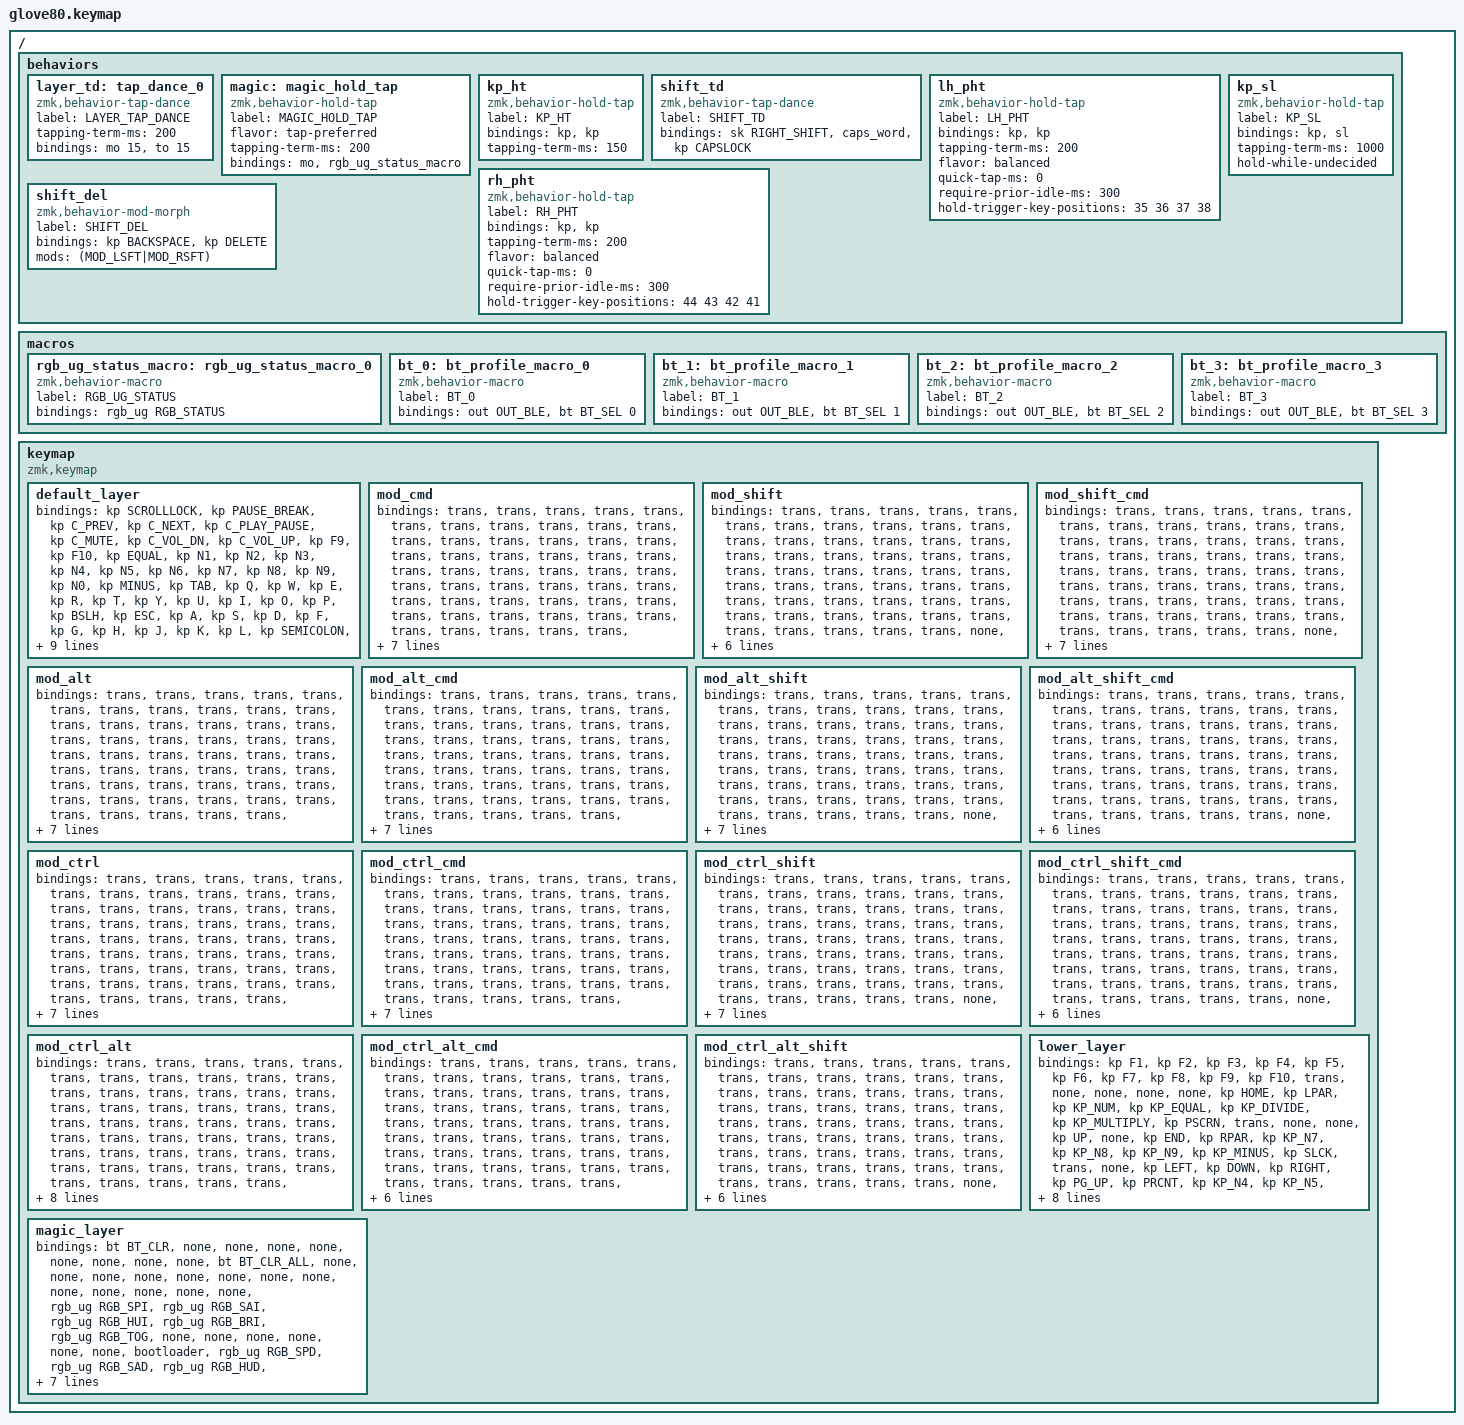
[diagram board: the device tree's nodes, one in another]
/*
 * Copyright (c) 2020 The ZMK Contributors
 *
 * SPDX-License-Identifier: MIT
 */

#include <behaviors.dtsi>
#include <dt-bindings/zmk/bt.h>
#include <dt-bindings/zmk/keys.h>
#include <dt-bindings/zmk/outputs.h>
#include <dt-bindings/zmk/rgb.h>

#define HYPER LC(LS(LG(LALT)))

// layers

#define DEFAULT 0
#define LOWER 1
#define MAGIC 2
#define FACTORY_TEST 3

/ {
    behaviors {
        // For the "layer" key, it'd nice to be able to use it as either a shift or a toggle.
        // Configure it as a tap dance, so the first tap (or hold) is a &mo and the second tap is a &to

        layer_td: tap_dance_0 {
            compatible = "zmk,behavior-tap-dance";
            label = "LAYER_TAP_DANCE";
            #binding-cells = <0>;
            tapping-term-ms = <200>;
            bindings = <&mo 15>, <&to 15>;
        };

        magic: magic_hold_tap {
            compatible = "zmk,behavior-hold-tap";
            label = "MAGIC_HOLD_TAP";
            #binding-cells = <2>;
            flavor = "tap-preferred";
            tapping-term-ms = <200>;
            bindings = <&mo>, <&rgb_ug_status_macro>;
        };

        kp_ht: kp_ht {
            compatible = "zmk,behavior-hold-tap";
            label = "KP_HT";
            bindings = <&kp>, <&kp>;

            #binding-cells = <2>;
            tapping-term-ms = <150>;
        };

        shift_td: shift_td {
            compatible = "zmk,behavior-tap-dance";
            label = "SHIFT_TD";
            #binding-cells = <0>;
            bindings = <&sk RIGHT_SHIFT>, <&caps_word>, <&kp CAPSLOCK>;
        };

        lh_pht: lh_pht {
            compatible = "zmk,behavior-hold-tap";
            label = "LH_PHT";
            bindings = <&kp>, <&kp>;

            #binding-cells = <2>;
            tapping-term-ms = <200>;
            flavor = "balanced";
            quick-tap-ms = <0>;
            require-prior-idle-ms = <300>;
            hold-trigger-key-positions = <35 36 37 38>;
        };

        rh_pht: rh_pht {
            compatible = "zmk,behavior-hold-tap";
            label = "RH_PHT";
            bindings = <&kp>, <&kp>;

            #binding-cells = <2>;
            tapping-term-ms = <200>;
            flavor = "balanced";
            quick-tap-ms = <0>;
            require-prior-idle-ms = <300>;
            hold-trigger-key-positions = <44 43 42 41>;
        };

        shift_del: shift_del {
            compatible = "zmk,behavior-mod-morph";
            label = "SHIFT_DEL";
            bindings = <&kp BACKSPACE>, <&kp DELETE>;

            #binding-cells = <0>;
            mods = <(MOD_LSFT|MOD_RSFT)>;
        };

        kp_sl: kp_sl {
            compatible = "zmk,behavior-hold-tap";
            label = "KP_SL";
            bindings = <&kp>, <&sl>;

            #binding-cells = <2>;
            tapping-term-ms = <1000>;
            hold-while-undecided;
        };
    };

    macros {
        rgb_ug_status_macro: rgb_ug_status_macro_0 {
            label = "RGB_UG_STATUS";
            compatible = "zmk,behavior-macro";
            #binding-cells = <0>;
            bindings = <&rgb_ug RGB_STATUS>;
        };

        bt_0: bt_profile_macro_0 {
            label = "BT_0";
            compatible = "zmk,behavior-macro";
            #binding-cells = <0>;
            bindings = <&out OUT_BLE &bt BT_SEL 0>;
        };

        bt_1: bt_profile_macro_1 {
            label = "BT_1";
            compatible = "zmk,behavior-macro";
            #binding-cells = <0>;
            bindings = <&out OUT_BLE &bt BT_SEL 1>;
        };

        bt_2: bt_profile_macro_2 {
            label = "BT_2";
            compatible = "zmk,behavior-macro";
            #binding-cells = <0>;
            bindings = <&out OUT_BLE &bt BT_SEL 2>;
        };

        bt_3: bt_profile_macro_3 {
            label = "BT_3";
            compatible = "zmk,behavior-macro";
            #binding-cells = <0>;
            bindings = <&out OUT_BLE &bt BT_SEL 3>;
        };
    };

    keymap {
        compatible = "zmk,keymap";

        default_layer {
            // ---------------------------------------------------------------------------------------------------------------------------------
            // |  F1   |  F2 |  F3 |  F4  |  F5  |                                                               |  F6   |  F7   |  F8  |   F9  |  F10 |
            // |  =    |  1  |  2  |  3   |  4   |  5   |                                                 |  6   |   7   |   8   |  9   |   0   |   -  |
            // |  TAB  |  Q  |  W  |  E   |  R   |  T   |                                                 |  Y   |   U   |   I   |  O   |   P   |   \  |
            // |  ESC  |  A  |  S  |  D   |  F   |  G   |                                                 |  H   |   J   |   K   |  L   |   ;   |   '  |
            // |   `   |  Z  |  X  |  C   |  V   |  B   | LSHFT | LCTRL | LOWER | | LGUI  | RCTRL | RSHFT |  N   |   M   |   ,   |  .   |   /   | PGUP |
            // | MAGIC | HOME| END | LEFT | RIGHT|      | BSPC  | DEL   | LALT  | | RALT  | RET   | SPACE |      |  UP   | DOWN  |  [   |   ]   | PGDN |

            bindings = <
&kp SCROLLLOCK  &kp PAUSE_BREAK  &kp C_PREV  &kp C_NEXT  &kp C_PLAY_PAUSE                                                                                                                &kp C_MUTE  &kp C_VOL_DN  &kp C_VOL_UP  &kp F9         &kp F10
&kp EQUAL       &kp N1           &kp N2      &kp N3      &kp N4            &kp N5                                                                                                &kp N6  &kp N7      &kp N8        &kp N9        &kp N0         &kp MINUS
&kp TAB         &kp Q            &kp W       &kp E       &kp R             &kp T                                                                                                 &kp Y   &kp U       &kp I         &kp O         &kp P          &kp BSLH
&kp ESC         &kp A            &kp S       &kp D       &kp F             &kp G                                                                                                 &kp H   &kp J       &kp K         &kp L         &kp SEMICOLON  &kp SQT
&kp GRAVE       &kp Z            &kp X       &kp C       &kp V             &kp B   &kp_sl LSHFT 2  &kp_sl LCMD 1   &layer_td      &kp_sl RCTRL 8  &kp_sl RGUI 1  &kp_sl RSHFT 2  &kp N   &kp M       &kp COMMA     &kp DOT       &kp FSLH       &kp PG_UP
&magic 16 0     &kp HOME         &kp END     &kp LEFT    &kp RIGHT                 &shift_del      &kp_sl LCTRL 8  &kp_sl LALT 4  &kp_sl RALT 4   &kp RET        &kp SPACE               &kp UP      &kp DOWN      &kp LBKT      &kp RBKT       &kp PG_DN
            >;
        };

        mod_cmd {
            bindings = <
&trans  &trans  &trans  &trans  &trans                                                                                                                             &trans  &trans  &trans  &trans  &trans
&trans  &trans  &trans  &trans  &trans  &trans                                                                                                             &trans  &trans  &trans  &trans  &trans  &trans
&trans  &trans  &trans  &trans  &trans  &trans                                                                                                             &trans  &trans  &trans  &trans  &trans  &trans
&trans  &trans  &trans  &trans  &trans  &trans                                                                                                             &trans  &trans  &trans  &trans  &trans  &trans
&trans  &trans  &trans  &trans  &trans  &trans  &kp_sl LG(LSHFT) 3  &none               &trans             &kp_sl RG(RCTRL) 9  &none   &kp_sl RG(RSHFT) 3  &trans  &trans  &trans  &trans  &trans  &trans
&trans  &trans  &trans  &trans  &trans          &trans              &kp_sl LG(LCTRL) 9  &kp_sl LG(LALT) 5  &kp_sl RG(RALT) 5   &trans  &trans                      &trans  &trans  &trans  &trans  &trans
            >;
        };

        mod_shift {
            bindings = <
&trans  &trans  &trans  &trans  &trans                                                                                                                  &trans  &trans  &trans  &trans  &trans
&trans  &trans  &trans  &trans  &trans  &trans                                                                                                  &trans  &trans  &trans  &trans  &trans  &trans
&trans  &trans  &trans  &trans  &trans  &trans                                                                                                  &trans  &trans  &trans  &trans  &trans  &trans
&trans  &trans  &trans  &trans  &trans  &trans                                                                                                  &trans  &trans  &trans  &trans  &trans  &trans
&trans  &trans  &trans  &trans  &trans  &trans  &none   &kp_sl LS(LGUI) 3    &trans             &kp_sl RS(RCTRL) 10  &kp_sl RS(RGUI) 3  &none   &trans  &trans  &trans  &trans  &trans  &trans
&trans  &trans  &trans  &trans  &trans          &trans  &kp_sl LS(LCTRL) 10  &kp_sl LS(LALT) 6  &kp_sl RS(RALT) 6    &trans             &trans          &trans  &trans  &trans  &trans  &trans
            >;
        };

        mod_shift_cmd {
            bindings = <
&trans  &trans  &trans  &trans  &trans                                                                                                                   &trans  &trans  &trans  &trans  &trans
&trans  &trans  &trans  &trans  &trans  &trans                                                                                                   &trans  &trans  &trans  &trans  &trans  &trans
&trans  &trans  &trans  &trans  &trans  &trans                                                                                                   &trans  &trans  &trans  &trans  &trans  &trans
&trans  &trans  &trans  &trans  &trans  &trans                                                                                                   &trans  &trans  &trans  &trans  &trans  &trans
&trans  &trans  &trans  &trans  &trans  &trans  &none   &none                    &trans                 &kp_sl RS(RG(RCTRL)) 11  &none   &none   &trans  &trans  &trans  &trans  &trans  &trans
&trans  &trans  &trans  &trans  &trans          &trans  &kp_sl LS(LG(LCTRL)) 11  &kp_sl LS(LG(LALT)) 7  &kp_sl RS(RG(RALT)) 7    &trans  &trans          &trans  &trans  &trans  &trans  &trans
            >;
        };

        mod_alt {
            bindings = <
&trans  &trans  &trans  &trans  &trans                                                                                                                               &trans  &trans  &trans  &trans  &trans
&trans  &trans  &trans  &trans  &trans  &trans                                                                                                               &trans  &trans  &trans  &trans  &trans  &trans
&trans  &trans  &trans  &trans  &trans  &trans                                                                                                               &trans  &trans  &trans  &trans  &trans  &trans
&trans  &trans  &trans  &trans  &trans  &trans                                                                                                               &trans  &trans  &trans  &trans  &trans  &trans
&trans  &trans  &trans  &trans  &trans  &trans  &kp_sl LA(LSHFT) 6  &kp_sl LA(LCMD) 5    &trans  &kp_sl RA(RCTRL) 12  &kp_sl RA(RCMD) 5  &kp_sl RA(RSHFT) 6  &trans  &trans  &trans  &trans  &trans  &trans
&trans  &trans  &trans  &trans  &trans          &trans              &kp_sl LA(LCTRL) 12  &none   &none                &trans             &trans                      &trans  &trans  &trans  &trans  &trans
            >;
        };

        mod_alt_cmd {
            bindings = <
&trans  &trans  &trans  &trans  &trans                                                                                                                                     &trans  &trans  &trans  &trans  &trans
&trans  &trans  &trans  &trans  &trans  &trans                                                                                                                     &trans  &trans  &trans  &trans  &trans  &trans
&trans  &trans  &trans  &trans  &trans  &trans                                                                                                                     &trans  &trans  &trans  &trans  &trans  &trans
&trans  &trans  &trans  &trans  &trans  &trans                                                                                                                     &trans  &trans  &trans  &trans  &trans  &trans
&trans  &trans  &trans  &trans  &trans  &trans  &kp_sl LA(LG(LSHIFT)) 7  &none                    &trans  &kp_sl RA(RG(RCTRL)) 13  &none   &kp_sl RA(RG(RSHFT)) 7  &trans  &trans  &trans  &trans  &trans  &trans
&trans  &trans  &trans  &trans  &trans          &trans                   &kp_sl LA(LG(LCTRL)) 13  &none   &none                    &trans  &trans                          &trans  &trans  &trans  &trans  &trans
            >;
        };

        mod_alt_shift {
            bindings = <
&trans  &trans  &trans  &trans  &trans                                                                                                                   &trans  &trans  &trans  &trans  &trans
&trans  &trans  &trans  &trans  &trans  &trans                                                                                                   &trans  &trans  &trans  &trans  &trans  &trans
&trans  &trans  &trans  &trans  &trans  &trans                                                                                                   &trans  &trans  &trans  &trans  &trans  &trans
&trans  &trans  &trans  &trans  &trans  &trans                                                                                                   &trans  &trans  &trans  &trans  &trans  &trans
&trans  &trans  &trans  &trans  &trans  &trans  &none   &kp_sl LS(LA(LCMD)) 7    &trans  &kp_sl RA(RS(RCTRL)) 14  &kp_sl RA(RS(RCMD)) 7  &none   &trans  &trans  &trans  &trans  &trans  &trans
&trans  &trans  &trans  &trans  &trans          &trans  &kp_sl LS(LA(LCTRL)) 14  &none   &none                    &trans                 &trans          &trans  &trans  &trans  &trans  &trans
            >;
        };

        mod_alt_shift_cmd {
            bindings = <
&trans  &trans  &trans  &trans  &trans                                                                                                &trans  &trans  &trans  &trans  &trans
&trans  &trans  &trans  &trans  &trans  &trans                                                                                &trans  &trans  &trans  &trans  &trans  &trans
&trans  &trans  &trans  &trans  &trans  &trans                                                                                &trans  &trans  &trans  &trans  &trans  &trans
&trans  &trans  &trans  &trans  &trans  &trans                                                                                &trans  &trans  &trans  &trans  &trans  &trans
&trans  &trans  &trans  &trans  &trans  &trans  &none   &none                  &trans  &kp RA(RS(RG(RCTRL)))  &none   &none   &trans  &trans  &trans  &trans  &trans  &trans
&trans  &trans  &trans  &trans  &trans          &trans  &kp LA(LS(LG(LCTRL)))  &none   &none                  &trans  &trans          &trans  &trans  &trans  &trans  &trans
            >;
        };

        mod_ctrl {
            bindings = <
&trans  &trans  &trans  &trans  &trans                                                                                                                                          &trans  &trans  &trans  &trans  &trans
&trans  &trans  &trans  &trans  &trans  &trans                                                                                                                          &trans  &trans  &trans  &trans  &trans  &trans
&trans  &trans  &trans  &trans  &trans  &trans                                                                                                                          &trans  &trans  &trans  &trans  &trans  &trans
&trans  &trans  &trans  &trans  &trans  &trans                                                                                                                          &trans  &trans  &trans  &trans  &trans  &trans
&trans  &trans  &trans  &trans  &trans  &trans  &kp_sl LC(LSHFT) 10  &kp_sl LC(LCMD) 9  &trans              &none               &kp_sl RC(RCMD) 9  &kp_sl RC(RSHFT) 10  &trans  &trans  &trans  &trans  &trans  &trans
&trans  &trans  &trans  &trans  &trans          &trans               &none              &kp_sl LC(LALT) 12  &kp_sl RC(RALT) 12  &trans             &trans                       &trans  &trans  &trans  &trans  &trans
            >;
        };

        mod_ctrl_cmd {
            bindings = <
&trans  &trans  &trans  &trans  &trans                                                                                                                                   &trans  &trans  &trans  &trans  &trans
&trans  &trans  &trans  &trans  &trans  &trans                                                                                                                   &trans  &trans  &trans  &trans  &trans  &trans
&trans  &trans  &trans  &trans  &trans  &trans                                                                                                                   &trans  &trans  &trans  &trans  &trans  &trans
&trans  &trans  &trans  &trans  &trans  &trans                                                                                                                   &trans  &trans  &trans  &trans  &trans  &trans
&trans  &trans  &trans  &trans  &trans  &trans  &kp_sl LC(LG(LSHFT)) 11  &none  &trans                  &none                   &none   &kp_sl RC(RG(RSHFT)) 11  &trans  &trans  &trans  &trans  &trans  &trans
&trans  &trans  &trans  &trans  &trans          &trans                   &none  &kp_sl LC(LG(LALT)) 13  &kp_sl RC(RG(RALT)) 13  &trans  &trans                           &trans  &trans  &trans  &trans  &trans
            >;
        };

        mod_ctrl_shift {
            bindings = <
&trans  &trans  &trans  &trans  &trans                                                                                                                                  &trans  &trans  &trans  &trans  &trans
&trans  &trans  &trans  &trans  &trans  &trans                                                                                                                  &trans  &trans  &trans  &trans  &trans  &trans
&trans  &trans  &trans  &trans  &trans  &trans                                                                                                                  &trans  &trans  &trans  &trans  &trans  &trans
&trans  &trans  &trans  &trans  &trans  &trans                                                                                                                  &trans  &trans  &trans  &trans  &trans  &trans
&trans  &trans  &trans  &trans  &trans  &trans  &none   &kp_sl LC(LS(LCMD)) 11  &trans                  &none                   &kp_sl LC(LS(LCMD)) 11  &none   &trans  &trans  &trans  &trans  &trans  &trans
&trans  &trans  &trans  &trans  &trans          &trans  &none                   &kp_sl LC(LS(LALT)) 14  &kp_sl RC(RS(RALT)) 14  &trans                  &trans          &trans  &trans  &trans  &trans  &trans
            >;
        };

        mod_ctrl_shift_cmd {
            bindings = <
&trans  &trans  &trans  &trans  &trans                                                                                             &trans  &trans  &trans  &trans  &trans
&trans  &trans  &trans  &trans  &trans  &trans                                                                             &trans  &trans  &trans  &trans  &trans  &trans
&trans  &trans  &trans  &trans  &trans  &trans                                                                             &trans  &trans  &trans  &trans  &trans  &trans
&trans  &trans  &trans  &trans  &trans  &trans                                                                             &trans  &trans  &trans  &trans  &trans  &trans
&trans  &trans  &trans  &trans  &trans  &trans  &none   &none  &trans                &none                 &none   &none   &trans  &trans  &trans  &trans  &trans  &trans
&trans  &trans  &trans  &trans  &trans          &trans  &none  &kp LS(LC(LG(LALT)))  &kp LS(LC(LG(RALT)))  &trans  &trans          &trans  &trans  &trans  &trans  &trans
            >;
        };

        mod_ctrl_alt {
            bindings = <
&trans  &trans  &trans  &trans  &trans                                                                                                                                   &trans  &trans  &trans  &trans  &trans
&trans  &trans  &trans  &trans  &trans  &trans                                                                                                                   &trans  &trans  &trans  &trans  &trans  &trans
&trans  &trans  &trans  &trans  &trans  &trans                                                                                                                   &trans  &trans  &trans  &trans  &trans  &trans
&trans  &trans  &trans  &trans  &trans  &trans                                                                                                                   &trans  &trans  &trans  &trans  &trans  &trans
&trans  &trans  &trans  &trans  &trans  &trans  &kp_sl LC(LA(LSHFT)) 14  &kp_sl LA(LC(LGUI)) 13  &trans  &none  &kp_sl RC(RA(RGUI)) 13  &kp_sl RC(RA(RSHFT)) 14  &trans  &trans  &trans  &trans  &trans  &trans
&trans  &trans  &trans  &trans  &trans          &trans                   &none                   &none   &none  &trans                  &trans                           &trans  &trans  &trans  &trans  &trans
            >;
        };

        mod_ctrl_alt_cmd {
            bindings = <
&trans  &trans  &trans  &trans  &trans                                                                                              &trans  &trans  &trans  &trans  &trans
&trans  &trans  &trans  &trans  &trans  &trans                                                                              &trans  &trans  &trans  &trans  &trans  &trans
&trans  &trans  &trans  &trans  &trans  &trans                                                                              &trans  &trans  &trans  &trans  &trans  &trans
&trans  &trans  &trans  &trans  &trans  &trans                                                                              &trans  &trans  &trans  &trans  &trans  &trans
&trans  &trans  &trans  &trans  &trans  &trans  &kp LC(LA(LG(LSHFT)))  &none  &trans  &none  &none   &kp RA(RC(RG(RSHFT)))  &trans  &trans  &trans  &trans  &trans  &trans
&trans  &trans  &trans  &trans  &trans          &trans                 &none  &none   &none  &trans  &trans                         &trans  &trans  &trans  &trans  &trans
            >;
        };

        mod_ctrl_alt_shift {
            bindings = <
&trans  &trans  &trans  &trans  &trans                                                                                            &trans  &trans  &trans  &trans  &trans
&trans  &trans  &trans  &trans  &trans  &trans                                                                            &trans  &trans  &trans  &trans  &trans  &trans
&trans  &trans  &trans  &trans  &trans  &trans                                                                            &trans  &trans  &trans  &trans  &trans  &trans
&trans  &trans  &trans  &trans  &trans  &trans                                                                            &trans  &trans  &trans  &trans  &trans  &trans
&trans  &trans  &trans  &trans  &trans  &trans  &none   &kp LS(LA(LC(LCMD)))  &none  &none  &kp RS(RA(RC(RCMD)))  &trans  &trans  &trans  &trans  &trans  &trans  &trans
&trans  &trans  &trans  &trans  &trans          &trans  &none                 &none  &none  &trans                &trans          &trans  &trans  &trans  &trans  &trans
            >;
        };

        lower_layer {
            bindings = <
&kp F1  &kp F2       &kp F3    &kp F4    &kp F5                                                                           &kp F6      &kp F7        &kp F8         &kp F9           &kp F10
&trans  &none        &none     &none     &none      &kp HOME                                                   &kp LPAR   &kp KP_NUM  &kp KP_EQUAL  &kp KP_DIVIDE  &kp KP_MULTIPLY  &kp PSCRN
&trans  &none        &none     &kp UP    &none      &kp END                                                    &kp RPAR   &kp KP_N7   &kp KP_N8     &kp KP_N9      &kp KP_MINUS     &kp SLCK
&trans  &none        &kp LEFT  &kp DOWN  &kp RIGHT  &kp PG_UP                                                  &kp PRCNT  &kp KP_N4   &kp KP_N5     &kp KP_N6      &kp KP_PLUS      &none
&trans  &kp K_CMENU  &none     &kp F11   &kp F12    &kp PG_DN  &trans  &trans  &to 0   &trans  &trans  &trans  &kp COMMA  &kp KP_N1   &kp KP_N2     &kp KP_N3      &kp KP_ENTER     &trans
&trans  &kp CAPS     &kp INS   &kp F11   &kp F12               &trans  &trans  &trans  &trans  &trans  &trans             &kp KP_N0   &kp KP_N0     &kp KP_DOT     &kp KP_ENTER     &trans
            >;
        };

        magic_layer {
            bindings = <
&bt BT_CLR   &none            &none            &none            &none                                                                                     &none  &none  &none  &none  &bt BT_CLR_ALL
&none        &none            &none            &none            &none            &none                                                             &none  &none  &none  &none  &none  &none
&none        &rgb_ug RGB_SPI  &rgb_ug RGB_SAI  &rgb_ug RGB_HUI  &rgb_ug RGB_BRI  &rgb_ug RGB_TOG                                                   &none  &none  &none  &none  &none  &none
&bootloader  &rgb_ug RGB_SPD  &rgb_ug RGB_SAD  &rgb_ug RGB_HUD  &rgb_ug RGB_BRD  &rgb_ug RGB_EFF                                                   &none  &none  &none  &none  &none  &bootloader
&sys_reset   &none            &none            &none            &none            &none            &bt_2  &bt_3  &none         &none  &none  &none  &none  &none  &none  &none  &none  &sys_reset
&none        &none            &none            &none            &none                             &bt_0  &bt_1  &out OUT_USB  &none  &none  &none         &none  &none  &none  &none  &to 0
            >;
        };
    };
};
